CM_ "IMPORT _stellantis_common.dbc";

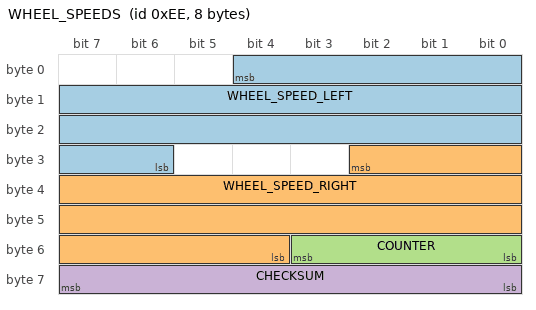
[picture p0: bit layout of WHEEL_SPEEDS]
BO_ 238 WHEEL_SPEEDS: 8 XXX
 SG_ WHEEL_SPEED_LEFT : 4|23@0+ (6e-06,0) [0|250] "kmh" XXX
 SG_ WHEEL_SPEED_RIGHT : 26|23@0+ (6e-06,0) [0|250] "kmh" XXX
 SG_ COUNTER : 51|4@0+ (1,0) [0|15] "" XXX
 SG_ CHECKSUM : 63|8@0+ (1,0) [0|255] "" XXX

BO_ 250 BRAKE_PRESSED_4: 8 XXX
 SG_ BRAKE_PRESSED_4 : 2|1@0+ (1,0) [0|1] "" XXX
